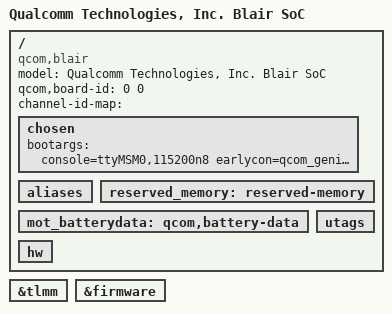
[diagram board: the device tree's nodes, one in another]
/* Copyright (c) 2023, The Linux Foundation. All rights reserved.
 *
 * This program is free software; you can redistribute it and/or modify
 * it under the terms of the GNU General Public License version 2 and
 * only version 2 as published by the Free Software Foundation.
 *
 * This program is distributed in the hope that it will be useful,
 * but WITHOUT ANY WARRANTY; without even the implied warranty of
 * MERCHANTABILITY or FITNESS FOR A PARTICULAR PURPOSE.  See the
 * GNU General Public License for more details.
 */

/* This file is derivated from blair.dts */

/dts-v1/;

#include "blair.dtsi"

/ {
	model = "Qualcomm Technologies, Inc. Blair SoC";
	compatible = "qcom,blair";
	qcom,board-id = <0 0>;
	channel-id-map = "";
/*
 * Some nodes need labels assigned to appear in __symbols__
 */
	chosen: chosen { };
	aliases: aliases { };
	reserved_memory: reserved-memory { };
	mot_batterydata: qcom,battery-data { };
	utags: utags { };
	hw: hw { };
};

&reserved_memory {
        /delete-node/ ramoops;
};

&tlmm {
	/delete-node/ nfc;
};

&firmware {
        /delete-node/ android;
};

&chosen {
	/delete-property/ bootargs;
};

/* bootargs originally copied from blair.dtsi by removing <loglevel=6 log_buf_len=256K> */
/* override bootargs in order to config loglevel and log_buf_len based on build variant */
&chosen {
	bootargs = "console=ttyMSM0,115200n8 earlycon=qcom_geni,0x04C8C000 qcom_geni_serial.con_enabled=1 swiotlb=noforce kernel.panic_on_rcu_stall=1 rcupdate.rcu_expedited=1 fw_devlink.strict=1 service_locator.enable=1 rcu_nocbs=0-7 kpti=off irqaffinity=0-1 cpufreq.default_governor=performance sysctl.kernel.sched_pelt_multiplier=4 no-steal-acc cgroup.memory=nokmem,nosocket printk.console_no_auto_verbose=1 kasan=off loop.max_part=7 can.stats_timer=0  firmware_class.path=/vendor/firmware_mnt/image pcie_ports=compat disable_dma32=on";
};

